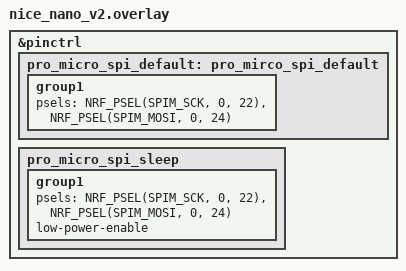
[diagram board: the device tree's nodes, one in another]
&pinctrl {
    pro_micro_spi_default: pro_mirco_spi_default {
        group1 {
            psels = <NRF_PSEL(SPIM_SCK, 0, 22)>,
                    <NRF_PSEL(SPIM_MOSI, 0, 24)>;
        };
    };

    pro_micro_spi_sleep: pro_micro_spi_sleep {
        group1 {
			psels = <NRF_PSEL(SPIM_SCK, 0, 22)>,
					<NRF_PSEL(SPIM_MOSI, 0, 24)>;
			low-power-enable;
        };
    };
};


